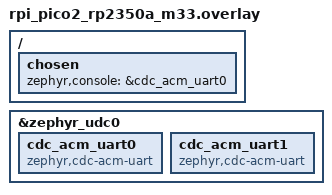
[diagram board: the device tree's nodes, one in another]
&zephyr_udc0 {
    // Control port
    cdc_acm_uart0: cdc_acm_uart0 {
        compatible = "zephyr,cdc-acm-uart";
    };
    // Data port
    cdc_acm_uart1: cdc_acm_uart1 {
        compatible = "zephyr,cdc-acm-uart";
    };
};

/ {
    chosen {
        zephyr,console = &cdc_acm_uart0;
    };
};
